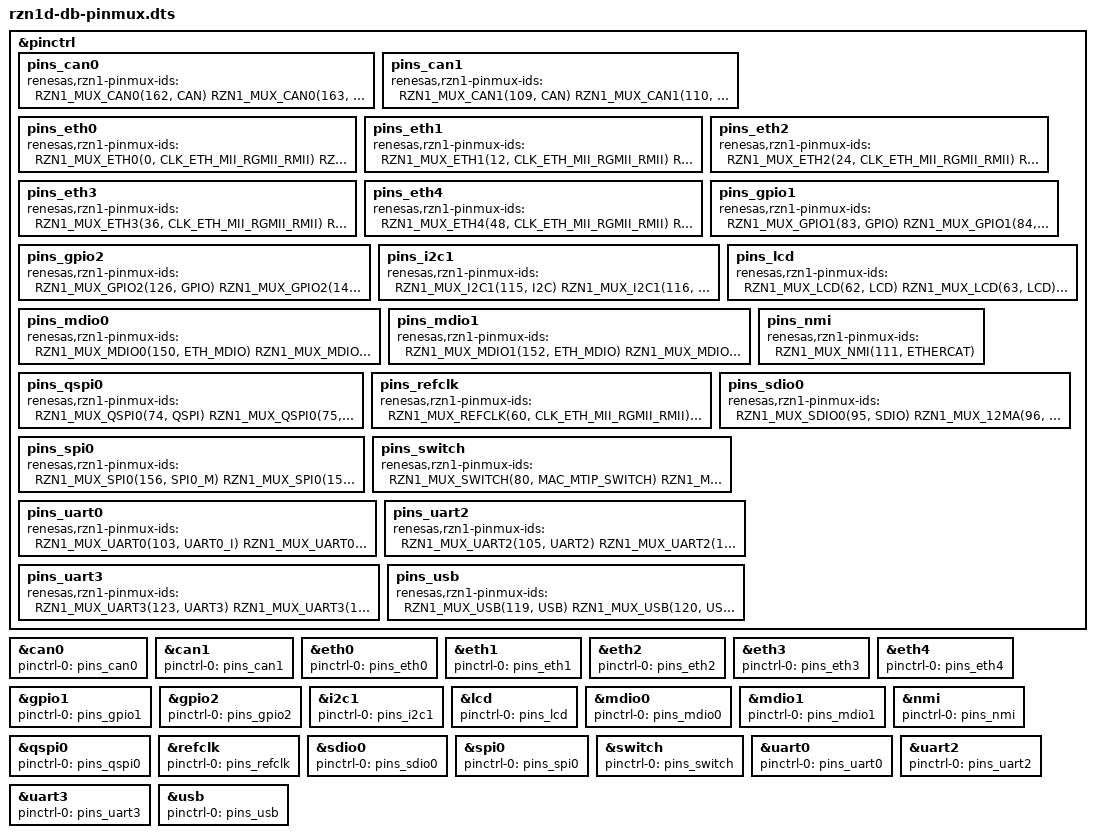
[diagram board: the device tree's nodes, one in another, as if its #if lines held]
/*
 * This file was autogenerated
 * DO NOT EDIT
 * (C) 2015-2016 Renesas Electronics Europe, LTD
 * All rights reserved.
 *
 * Redistribution and use in source and binary forms, with or without
 * modification, are permitted provided that the following conditions are met:
 *
 * 1. Redistributions of source code must retain the above copyright notice,
 * this list of conditions and the following disclaimer.
 *
 * 2. Redistributions in binary form must reproduce the above copyright notice,
 * this list of conditions and the following disclaimer in the documentation
 * and/or other materials provided with the distribution.
 *
 * THIS SOFTWARE IS PROVIDED BY THE COPYRIGHT HOLDERS AND CONTRIBUTORS "AS IS"
 * AND ANY EXPRESS OR IMPLIED WARRANTIES, INCLUDING, BUT NOT LIMITED TO, THE
 * IMPLIED WARRANTIES OF MERCHANTABILITY AND FITNESS FOR A PARTICULAR PURPOSE
 * ARE DISCLAIMED. IN NO EVENT SHALL THE COPYRIGHT HOLDER OR CONTRIBUTORS BE
 * LIABLE FOR ANY DIRECT, INDIRECT, INCIDENTAL, SPECIAL, EXEMPLARY, OR
 * CONSEQUENTIAL DAMAGES (INCLUDING, BUT NOT LIMITED TO, PROCUREMENT OF
 * SUBSTITUTE GOODS OR SERVICES; LOSS OF USE, DATA, OR PROFITS; OR BUSINESS
 * INTERRUPTION) HOWEVER CAUSED AND ON ANY THEORY OF LIABILITY, WHETHER IN
 * CONTRACT, STRICT LIABILITY, OR TORT (INCLUDING NEGLIGENCE OR OTHERWISE)
 * ARISING IN ANY WAY OUT OF THE USE OF THIS SOFTWARE, EVEN IF ADVISED OF THE
 * POSSIBILITY OF SUCH DAMAGE.
 */

#include "rzn1.dtsi"

/*
 * AUTOGENERATED DO NOT EDIT
 *
 * Renesas RZ/N1D Demo Board
 * This file only sets the pin function by default.
 *
 * You can override the default mux pullup/down and drive by
 * defining the following macros in the board file before
 * including this.
 */

#ifndef RZN1_MUX_DEFAULT
#define RZN1_MUX_DEFAULT RZN1_MUX
#endif

#ifndef RZN1_MUX_CAN0
#define RZN1_MUX_CAN0 RZN1_MUX_6MA
#endif
#ifndef RZN1_MUX_CAN1
#define RZN1_MUX_CAN1 RZN1_MUX_6MA
#endif
#ifndef RZN1_MUX_ETH0
#define RZN1_MUX_ETH0 RZN1_MUX_PNONE_6MA
#endif
#ifndef RZN1_MUX_ETH1
#define RZN1_MUX_ETH1 RZN1_MUX_PNONE_6MA
#endif
#ifndef RZN1_MUX_ETH2
#define RZN1_MUX_ETH2 RZN1_MUX_PNONE_6MA
#endif
#ifndef RZN1_MUX_ETH3
#define RZN1_MUX_ETH3 RZN1_MUX_PNONE_6MA
#endif
#ifndef RZN1_MUX_ETH4
#define RZN1_MUX_ETH4 RZN1_MUX_PNONE_6MA
#endif
#ifndef RZN1_MUX_GPIO
#define RZN1_MUX_GPIO RZN1_MUX_DEFAULT
#endif
#ifndef RZN1_MUX_GPIO1
#define RZN1_MUX_GPIO1 RZN1_MUX_GPIO
#endif
#ifndef RZN1_MUX_GPIO2
#define RZN1_MUX_GPIO2 RZN1_MUX_GPIO
#endif
#ifndef RZN1_MUX_I2C1
#define RZN1_MUX_I2C1 RZN1_MUX_12MA
#endif
#ifndef RZN1_MUX_LCD
#define RZN1_MUX_LCD RZN1_MUX_DEFAULT
#endif
#ifndef RZN1_MUX_MDIO
#define RZN1_MUX_MDIO RZN1_MUX_DEFAULT
#endif
#ifndef RZN1_MUX_MDIO0
#define RZN1_MUX_MDIO0 RZN1_MUX_MDIO
#endif
#ifndef RZN1_MUX_MDIO1
#define RZN1_MUX_MDIO1 RZN1_MUX_MDIO
#endif
#ifndef RZN1_MUX_NMI
#define RZN1_MUX_NMI RZN1_MUX_DEFAULT
#endif
#ifndef RZN1_MUX_QSPI0
#define RZN1_MUX_QSPI0 RZN1_MUX_PNONE
#endif
#ifndef RZN1_MUX_REFCLK
#define RZN1_MUX_REFCLK RZN1_MUX_PNONE
#endif
#ifndef RZN1_MUX_SDIO
#define RZN1_MUX_SDIO RZN1_MUX_DEFAULT
#endif
#ifndef RZN1_MUX_SDIO0
#define RZN1_MUX_SDIO0 RZN1_MUX_SDIO
#endif
#ifndef RZN1_MUX_SPI
#define RZN1_MUX_SPI RZN1_MUX_DEFAULT
#endif
#ifndef RZN1_MUX_SPI0
#define RZN1_MUX_SPI0 RZN1_MUX_SPI
#endif
#ifndef RZN1_MUX_SWITCH
#define RZN1_MUX_SWITCH RZN1_MUX_DEFAULT
#endif
#ifndef RZN1_MUX_UART0
#define RZN1_MUX_UART0 RZN1_MUX_PNONE
#endif
#ifndef RZN1_MUX_UART2
#define RZN1_MUX_UART2 RZN1_MUX_PNONE
#endif
#ifndef RZN1_MUX_UART
#define RZN1_MUX_UART RZN1_MUX_DEFAULT
#endif
#ifndef RZN1_MUX_UART3
#define RZN1_MUX_UART3 RZN1_MUX_UART
#endif
#ifndef RZN1_MUX_USB
#define RZN1_MUX_USB RZN1_MUX_DEFAULT
#endif

&pinctrl {
	pins_can0: pins_can0 {
		renesas,rzn1-pinmux-ids = <
			RZN1_MUX_CAN0(162, CAN)		/* CAN0_TXD */
			RZN1_MUX_CAN0(163, CAN)		/* CAN0_RXD */
		>;
	};
	pins_can1: pins_can1 {
		renesas,rzn1-pinmux-ids = <
			RZN1_MUX_CAN1(109, CAN)		/* CAN1_TXD */
			RZN1_MUX_CAN1(110, CAN)		/* CAN1_RXD */
		>;
	};
	pins_eth0: pins_eth0 {
		renesas,rzn1-pinmux-ids = <
			RZN1_MUX_ETH0(0, CLK_ETH_MII_RGMII_RMII)	/* ETH0_TXCLK */
			RZN1_MUX_ETH0(1, CLK_ETH_MII_RGMII_RMII)	/* ETH0_TXD[0] */
			RZN1_MUX_ETH0(2, CLK_ETH_MII_RGMII_RMII)	/* ETH0_TXD[1] */
			RZN1_MUX_ETH0(3, CLK_ETH_MII_RGMII_RMII)	/* ETH0_TXD[2] */
			RZN1_MUX_ETH0(4, CLK_ETH_MII_RGMII_RMII)	/* ETH0_TXD[3] */
			RZN1_MUX_ETH0(5, CLK_ETH_MII_RGMII_RMII)	/* ETH0_TXEN */
			RZN1_MUX_ETH0(6, CLK_ETH_MII_RGMII_RMII)	/* ETH0_RXCLK */
			RZN1_MUX_ETH0(7, CLK_ETH_MII_RGMII_RMII)	/* ETH0_RXD[0] */
			RZN1_MUX_ETH0(8, CLK_ETH_MII_RGMII_RMII)	/* ETH0_RXD[1] */
			RZN1_MUX_ETH0(9, CLK_ETH_MII_RGMII_RMII)	/* ETH0_RXD[2] */
			RZN1_MUX_ETH0(10, CLK_ETH_MII_RGMII_RMII)	/* ETH0_RXD[3] */
			RZN1_MUX_ETH0(11, CLK_ETH_MII_RGMII_RMII)	/* ETH0_RXDV */
		>;
	};
	pins_eth1: pins_eth1 {
		renesas,rzn1-pinmux-ids = <
			RZN1_MUX_ETH1(12, CLK_ETH_MII_RGMII_RMII)	/* ETH1_TXCLK */
			RZN1_MUX_ETH1(13, CLK_ETH_MII_RGMII_RMII)	/* ETH1_TXD[0] */
			RZN1_MUX_ETH1(14, CLK_ETH_MII_RGMII_RMII)	/* ETH1_TXD[1] */
			RZN1_MUX_ETH1(15, CLK_ETH_MII_RGMII_RMII)	/* ETH1_TXD[2] */
			RZN1_MUX_ETH1(16, CLK_ETH_MII_RGMII_RMII)	/* ETH1_TXD[3] */
			RZN1_MUX_ETH1(17, CLK_ETH_MII_RGMII_RMII)	/* ETH1_TXEN */
			RZN1_MUX_ETH1(18, CLK_ETH_MII_RGMII_RMII)	/* ETH1_RXCLK */
			RZN1_MUX_ETH1(19, CLK_ETH_MII_RGMII_RMII)	/* ETH1_RXD[0] */
			RZN1_MUX_ETH1(20, CLK_ETH_MII_RGMII_RMII)	/* ETH1_RXD[1] */
			RZN1_MUX_ETH1(21, CLK_ETH_MII_RGMII_RMII)	/* ETH1_RXD[2] */
			RZN1_MUX_ETH1(22, CLK_ETH_MII_RGMII_RMII)	/* ETH1_RXD[3] */
			RZN1_MUX_ETH1(23, CLK_ETH_MII_RGMII_RMII)	/* ETH1_RXDV */
		>;
	};
	pins_eth2: pins_eth2 {
		renesas,rzn1-pinmux-ids = <
			RZN1_MUX_ETH2(24, CLK_ETH_MII_RGMII_RMII)	/* ETH2_TXCLK */
			RZN1_MUX_ETH2(25, CLK_ETH_MII_RGMII_RMII)	/* ETH2_TXD[0] */
			RZN1_MUX_ETH2(26, CLK_ETH_MII_RGMII_RMII)	/* ETH2_TXD[1] */
			RZN1_MUX_ETH2(27, CLK_ETH_MII_RGMII_RMII)	/* ETH2_TXD[2] */
			RZN1_MUX_ETH2(28, CLK_ETH_MII_RGMII_RMII)	/* ETH2_TXD[3] */
			RZN1_MUX_ETH2(29, CLK_ETH_MII_RGMII_RMII)	/* ETH2_TXEN */
			RZN1_MUX_ETH2(30, CLK_ETH_MII_RGMII_RMII)	/* ETH2_RXCLK */
			RZN1_MUX_ETH2(31, CLK_ETH_MII_RGMII_RMII)	/* ETH2_RXD[0] */
			RZN1_MUX_ETH2(32, CLK_ETH_MII_RGMII_RMII)	/* ETH2_RXD[1] */
			RZN1_MUX_ETH2(33, CLK_ETH_MII_RGMII_RMII)	/* ETH2_RXD[2] */
			RZN1_MUX_ETH2(34, CLK_ETH_MII_RGMII_RMII)	/* ETH2_RXD[3] */
			RZN1_MUX_ETH2(35, CLK_ETH_MII_RGMII_RMII)	/* ETH2_RXDV */
		>;
	};
	pins_eth3: pins_eth3 {
		renesas,rzn1-pinmux-ids = <
			RZN1_MUX_ETH3(36, CLK_ETH_MII_RGMII_RMII)	/* ETH3_TXCLK */
			RZN1_MUX_ETH3(37, CLK_ETH_MII_RGMII_RMII)	/* ETH3_TXD[0] */
			RZN1_MUX_ETH3(38, CLK_ETH_MII_RGMII_RMII)	/* ETH3_TXD[1] */
			RZN1_MUX_ETH3(39, CLK_ETH_MII_RGMII_RMII)	/* ETH3_TXD[2] */
			RZN1_MUX_ETH3(40, CLK_ETH_MII_RGMII_RMII)	/* ETH3_TXD[3] */
			RZN1_MUX_ETH3(41, CLK_ETH_MII_RGMII_RMII)	/* ETH3_TXEN */
			RZN1_MUX_ETH3(42, CLK_ETH_MII_RGMII_RMII)	/* ETH3_RXCLK */
			RZN1_MUX_ETH3(43, CLK_ETH_MII_RGMII_RMII)	/* ETH3_RXD[0] */
			RZN1_MUX_ETH3(44, CLK_ETH_MII_RGMII_RMII)	/* ETH3_RXD[1] */
			RZN1_MUX_ETH3(45, CLK_ETH_MII_RGMII_RMII)	/* ETH3_RXD[2] */
			RZN1_MUX_ETH3(46, CLK_ETH_MII_RGMII_RMII)	/* ETH3_RXD[3] */
			RZN1_MUX_ETH3(47, CLK_ETH_MII_RGMII_RMII)	/* ETH3_RXDV */
		>;
	};
	pins_eth4: pins_eth4 {
		renesas,rzn1-pinmux-ids = <
			RZN1_MUX_ETH4(48, CLK_ETH_MII_RGMII_RMII)	/* ETH4_TXCLK */
			RZN1_MUX_ETH4(49, CLK_ETH_MII_RGMII_RMII)	/* ETH4_TXD[0] */
			RZN1_MUX_ETH4(50, CLK_ETH_MII_RGMII_RMII)	/* ETH4_TXD[1] */
			RZN1_MUX_ETH4(51, CLK_ETH_MII_RGMII_RMII)	/* ETH4_TXD[2] */
			RZN1_MUX_ETH4(52, CLK_ETH_MII_RGMII_RMII)	/* ETH4_TXD[3] */
			RZN1_MUX_ETH4(53, CLK_ETH_MII_RGMII_RMII)	/* ETH4_TXEN */
			RZN1_MUX_ETH4(54, CLK_ETH_MII_RGMII_RMII)	/* ETH4_RXCLK */
			RZN1_MUX_ETH4(55, CLK_ETH_MII_RGMII_RMII)	/* ETH4_RXD[0] */
			RZN1_MUX_ETH4(56, CLK_ETH_MII_RGMII_RMII)	/* ETH4_RXD[1] */
			RZN1_MUX_ETH4(57, CLK_ETH_MII_RGMII_RMII)	/* ETH4_RXD[2] */
			RZN1_MUX_ETH4(58, CLK_ETH_MII_RGMII_RMII)	/* ETH4_RXD[3] */
			RZN1_MUX_ETH4(59, CLK_ETH_MII_RGMII_RMII)	/* ETH4_RXDV */
		>;
	};
	pins_gpio1: pins_gpio1 {
		renesas,rzn1-pinmux-ids = <
			RZN1_MUX_GPIO1(83, GPIO)	/* GPIO1B[14] */
			RZN1_MUX_GPIO1(84, GPIO)	/* GPIO1B[15] */
			RZN1_MUX_GPIO1(85, GPIO)	/* GPIO1B[16] */
			RZN1_MUX_GPIO1(86, GPIO)	/* GPIO1B[17] */
			RZN1_MUX_GPIO1(87, GPIO)	/* GPIO1B[18] */
			RZN1_MUX_GPIO1(88, GPIO)	/* GPIO1B[19] */
			RZN1_MUX_GPIO1(89, GPIO)	/* GPIO1B[20] */
			RZN1_MUX_GPIO1(90, GPIO)	/* GPIO1B[21] */
			RZN1_MUX_GPIO1(91, GPIO)	/* GPIO1B[22] */
			RZN1_MUX_GPIO1(92, GPIO)	/* GPIO1B[23] */
			RZN1_MUX_GPIO1(93, GPIO)	/* GPIO1B[24] */
			RZN1_MUX_GPIO1(94, GPIO)	/* Eth PHY Reset (GPIO1B[25]) */
			RZN1_MUX_GPIO1(117, GPIO)	/* GPIO1A[27] */
			RZN1_MUX_GPIO1(118, GPIO)	/* Eth3 IRQ (GPIO1A[28]) */
			RZN1_MUX_GPIO1(154, GPIO)	/* MDC PHY1 GPIO (GPIO1B[30]) */
			RZN1_MUX_GPIO1(155, GPIO)	/* MDIO PHY1 GPIO (GPIO1B[31]) */
		>;
	};
	pins_gpio2: pins_gpio2 {
		renesas,rzn1-pinmux-ids = <
			RZN1_MUX_GPIO2(126, GPIO)	/* Eth2 IRQ (GPIO2A[4]) */
			RZN1_MUX_GPIO2(146, GPIO)	/* Eth1 IRQ (GPIO2A[24]) */
			RZN1_MUX_GPIO2(147, GPIO)	/* Eth4 IRQ (GPIO2A[25]) */
			RZN1_MUX_GPIO2(148, GPIO)	/* Touch IRQ (GPIO2A[26]) */
			RZN1_MUX_GPIO2(149, GPIO)	/* Eth5 IRQ (GPIO2A[27]) */
		>;
	};
	pins_i2c1: pins_i2c1 {
		renesas,rzn1-pinmux-ids = <
			RZN1_MUX_I2C1(115, I2C)		/* I2C1_SCL */
			RZN1_MUX_I2C1(116, I2C)		/* I2C1_SDA */
		>;
	};
	pins_lcd: pins_lcd {
		renesas,rzn1-pinmux-ids = <
			RZN1_MUX_LCD(62, LCD)		/* LCD_R[1] */
			RZN1_MUX_LCD(63, LCD)		/* LCD_G[1] */
			RZN1_MUX_LCD(64, LCD)		/* LCD_B[1] */
			RZN1_MUX_LCD(65, LCD)		/* LCD_R[2] */
			RZN1_MUX_LCD(66, LCD)		/* LCD_G[2] */
			RZN1_MUX_LCD(67, LCD)		/* LCD_B[2] */
			RZN1_MUX_LCD(68, LCD)		/* LCD_R[3] */
			RZN1_MUX_LCD(69, LCD)		/* LCD_G[3] */
			RZN1_MUX_LCD(70, LCD)		/* LCD_B[3] */
			RZN1_MUX_LCD(71, LCD)		/* LCD_R[4] */
			RZN1_MUX_LCD(72, LCD)		/* LCD_G[4] */
			RZN1_MUX_LCD(73, LCD)		/* LCD_B[4] */
			RZN1_MUX_LCD(127, LCD)		/* LCD_PWM[0] */
			RZN1_MUX_LCD(128, LCD)		/* LCD_PCLK */
			RZN1_MUX_LCD(129, LCD)		/* LCD_HSYNC */
			RZN1_MUX_LCD(130, LCD)		/* LCD_VSYNC */
			RZN1_MUX_LCD(131, LCD)		/* LCD_DE */
			RZN1_MUX_LCD(132, LCD)		/* LCD_PE */
			RZN1_MUX_LCD(133, LCD)		/* LCD_PWM[1] */
			RZN1_MUX_LCD(134, LCD)		/* LCD_R[5] */
			RZN1_MUX_LCD(135, LCD)		/* LCD_R[0] */
			RZN1_MUX_LCD(136, LCD)		/* LCD_G[0] */
			RZN1_MUX_LCD(137, LCD)		/* LCD_B[0] */
			RZN1_MUX_LCD(138, LCD)		/* LCD_R[6] */
			RZN1_MUX_LCD(139, LCD)		/* LCD_G[6] */
			RZN1_MUX_LCD(140, LCD)		/* LCD_B[6] */
			RZN1_MUX_LCD(141, LCD)		/* LCD_R[7] */
			RZN1_MUX_LCD(142, LCD)		/* LCD_G[7] */
			RZN1_MUX_LCD(143, LCD)		/* LCD_B[7] */
			RZN1_MUX_LCD(144, LCD)		/* LCD_G[5] */
			RZN1_MUX_LCD(145, LCD)		/* LCD_B[5] */
		>;
	};
	pins_mdio0: pins_mdio0 {
		renesas,rzn1-pinmux-ids = <
			RZN1_MUX_MDIO0(150, ETH_MDIO)	/* MDIO0_MDC */
			RZN1_MUX_MDIO0(151, ETH_MDIO)	/* MDIO0_MDIO */
			RZN1_MUX_MDIO0(170, MDIO_MUX_MAC0)	/* MDIO0_MUX_MAC0 */
		>;
	};
	pins_mdio1: pins_mdio1 {
		renesas,rzn1-pinmux-ids = <
			RZN1_MUX_MDIO1(152, ETH_MDIO)	/* MDIO1_MDC */
			RZN1_MUX_MDIO1(153, ETH_MDIO)	/* MDIO1_MDIO */
			RZN1_MUX_MDIO1(171, MDIO_MUX_SWITCH)	/* MDIO1_MUX_SWITCH */
		>;
	};
	pins_nmi: pins_nmi {
		renesas,rzn1-pinmux-ids = <
			RZN1_MUX_NMI(111, ETHERCAT)	/* NMI_CORTEXM[3] */
		>;
	};
	pins_qspi0: pins_qspi0 {
		renesas,rzn1-pinmux-ids = <
			RZN1_MUX_QSPI0(74, QSPI)	/* QSPI0_CS_N[0] */
			RZN1_MUX_QSPI0(75, QSPI)	/* QSPI0_IO[3] */
			RZN1_MUX_QSPI0(76, QSPI)	/* QSPI0_IO[2] */
			RZN1_MUX_QSPI0(77, QSPI)	/* QSPI0_IO[1] */
			RZN1_MUX_QSPI0(78, QSPI)	/* QSPI0_IO[0] */
			RZN1_MUX_QSPI0(79, QSPI)	/* QSPI0_CLK */
		>;
	};
	pins_refclk: pins_refclk {
		renesas,rzn1-pinmux-ids = <
			RZN1_MUX_REFCLK(60, CLK_ETH_MII_RGMII_RMII)	/* REFCLK_RGMII */
			RZN1_MUX_REFCLK(61, CLK_ETH_NAND)	/* REFCLK_MII[1] */
		>;
	};
	pins_sdio0: pins_sdio0 {
		renesas,rzn1-pinmux-ids = <
			RZN1_MUX_SDIO0(95, SDIO)	/* SDIO0_CMD */
			RZN1_MUX_12MA(96, SDIO)		/* SDIO0_CLK */
			RZN1_MUX_SDIO0(97, SDIO)	/* SDIO0_IO[0] */
			RZN1_MUX_SDIO0(98, SDIO)	/* SDIO0_IO[1] */
			RZN1_MUX_SDIO0(99, SDIO)	/* SDIO0_IO[2] */
			RZN1_MUX_SDIO0(100, SDIO)	/* SDIO0_IO[3] */
			RZN1_MUX_SDIO0(101, SDIO_E)	/* SDIO0_CD_N */
			RZN1_MUX_SDIO0(102, SDIO_E)	/* SDIO0_WP */
		>;
	};
	pins_spi0: pins_spi0 {
		renesas,rzn1-pinmux-ids = <
			RZN1_MUX_SPI0(156, SPI0_M)	/* SPI0_CLK */
			RZN1_MUX_SPI0(157, SPI0_M)	/* SPI0_MOSI */
			RZN1_MUX_SPI0(158, SPI0_M)	/* SPI0_MISO */
			RZN1_MUX_SPI0(159, SPI0_M)	/* SPI0_SS_N[0] */
		>;
	};
	pins_switch: pins_switch {
		renesas,rzn1-pinmux-ids = <
			RZN1_MUX_SWITCH(80, MAC_MTIP_SWITCH)	/* SWITCH_MII_LINK[5] */
			RZN1_MUX_SWITCH(81, MAC_MTIP_SWITCH)	/* SWITCH_MII_LINK[4] */
			RZN1_MUX_SWITCH(82, MAC_MTIP_SWITCH)	/* SWITCH_MII_LINK[3] */
			RZN1_MUX_SWITCH(114, MAC_MTIP_SWITCH)	/* SWITCH_MII_LINK[2] */
		>;
	};
	pins_uart0: pins_uart0 {
		renesas,rzn1-pinmux-ids = <
			RZN1_MUX_UART0(103, UART0_I)	/* UART0_TXD */
			RZN1_MUX_UART0(104, UART0_I)	/* UART0_RXD */
		>;
	};
	pins_uart2: pins_uart2 {
		renesas,rzn1-pinmux-ids = <
			RZN1_MUX_UART2(105, UART2)	/* UART2_TXD */
			RZN1_MUX_UART2(106, UART2)	/* UART2_RXD */
			RZN1_MUX_UART2(107, UART2)	/* UART2_RTS_N */
			RZN1_MUX_UART2(108, UART2)	/* UART2_CTS_N */
		>;
	};
	pins_uart3: pins_uart3 {
		renesas,rzn1-pinmux-ids = <
			RZN1_MUX_UART3(123, UART3)	/* UART3_TXD */
			RZN1_MUX_UART3(124, UART3)	/* UART3_RXD */
			RZN1_MUX_UART3(125, UART3)	/* UART3_RTS_N */
		>;
	};
	pins_usb: pins_usb {
		renesas,rzn1-pinmux-ids = <
			RZN1_MUX_USB(119, USB)		/* USB_PPON[1] */
			RZN1_MUX_USB(120, USB)		/* USB_OC[1] */
			RZN1_MUX_USB(121, USB)		/* USB_PPON[2] */
			RZN1_MUX_USB(122, USB)		/* USB_OC[2] */
		>;
	};
};

&can0 {
	pinctrl-names = "default";
	pinctrl-0 = <&pins_can0>;
};
&can1 {
	pinctrl-names = "default";
	pinctrl-0 = <&pins_can1>;
};
&eth0 {
	pinctrl-names = "default";
	pinctrl-0 = <&pins_eth0>;
};
&eth1 {
	pinctrl-names = "default";
	pinctrl-0 = <&pins_eth1>;
};
&eth2 {
	pinctrl-names = "default";
	pinctrl-0 = <&pins_eth2>;
};
&eth3 {
	pinctrl-names = "default";
	pinctrl-0 = <&pins_eth3>;
};
&eth4 {
	pinctrl-names = "default";
	pinctrl-0 = <&pins_eth4>;
};
&gpio1 {
	pinctrl-names = "default";
	pinctrl-0 = <&pins_gpio1>;
};
&gpio2 {
	pinctrl-names = "default";
	pinctrl-0 = <&pins_gpio2>;
};
&i2c1 {
	pinctrl-names = "default";
	pinctrl-0 = <&pins_i2c1>;
};
&lcd {
	pinctrl-names = "default";
	pinctrl-0 = <&pins_lcd>;
};
&mdio0 {
	pinctrl-names = "default";
	pinctrl-0 = <&pins_mdio0>;
};
&mdio1 {
	pinctrl-names = "default";
	pinctrl-0 = <&pins_mdio1>;
};
&nmi {
	pinctrl-names = "default";
	pinctrl-0 = <&pins_nmi>;
};
&qspi0 {
	pinctrl-names = "default";
	pinctrl-0 = <&pins_qspi0>;
};
&refclk {
	pinctrl-names = "default";
	pinctrl-0 = <&pins_refclk>;
};
&sdio0 {
	pinctrl-names = "default";
	pinctrl-0 = <&pins_sdio0>;
};
&spi0 {
	pinctrl-names = "default";
	pinctrl-0 = <&pins_spi0>;
};
&switch {
	pinctrl-names = "default";
	pinctrl-0 = <&pins_switch>;
};
&uart0 {
	pinctrl-names = "default";
	pinctrl-0 = <&pins_uart0>;
};
&uart2 {
	pinctrl-names = "default";
	pinctrl-0 = <&pins_uart2>;
};
&uart3 {
	pinctrl-names = "default";
	pinctrl-0 = <&pins_uart3>;
};
&usb {
	pinctrl-names = "default";
	pinctrl-0 = <&pins_usb>;
};

/*
 * This is the compressed Renesas Pinmux Web App data structure; this is
 * used to allow uploading this file back into the web app, make some
 * more changes and generate/save the DTS again. It is not used by Linux
 * in any way.
 */
#ifdef JSON_PRESET
N4IgdghgtgpiBcIBKMwwM4XQAiQLQHoA5ARgBFsyYoB7bAIRogCcATEAGhAAcIBjANYQA5nEQwALAAYpnHjGYBLbgAsFEADboEAb
RABhAIKk5RogCY5AUQAqACRLX7lrrbsBmJ3YleArHIBxAAUASQB5FxBg8M8uEPN9SIAZfTI5AFkycMcuTPDIonSQuQBFAGVQnOQr
ADF9JIBpOTKssKqKkPaAdRCbfTs5AFVDJBsq4dHYkAmbHy5BsvoQAF0uYW5FGgB9SFhteFAATktEKwAXFXdsEKQSuRJzR1OL7CC7
AE1cDBgz+/MANgQIEy+leHxI2GiYT+AHYgXkwmD3hCofd3CcQOcVOZrrd7r4MViITc7lwSL5PM8VBJcaSQOSfIgbDQAK58FS0/H+
Km+TkAXzWGxo+x0MN8EhIMP+HDFEphMJl4slAA5FXLDmqSMqpJrlSRdeZde5dRJdb5ddLZVqFVblarbRqrYcdU79U7DU7jU7TU7z
U7LUrDjbA/bA47xeYZGrI26I1IPXGvXGfXG/XGAxJI8HM1JQznw5mSC6IyRY4WE4Wk4WU4W04WM49s48848C+ZI9HHp2K+2q+2a+
26+2G+Ym+YW+Y2+5i5n3GXzOjo+4++4B+5zb5fFLxxxNzC7ebV+5/tKj/8FWfVWeNUeYTrb/rb4bb8bb6bb4eJO4pRxbwrN3q4q7
r4gEbiB5LSgB5L/uBIHAYBGq+EW5imkh8Ybsh0oSFKhwathd46vhUj6kRhpEcaRGmkR5pEVh8pSAqRGqkReHykWv4Sl+HASMcyqH
KenGfiQEgCcJF6cVe/wkEGv5SYcqq+P8o6HPqinKYaikUhSu7/FpqG6euG4GYpHAoRIIEamZvjOr+imHIedmnnZ/5FnBvhSP8uEb
h5uF0TCy7cfKq6yfJr6ecq77hYe4VYeS9ncXFsXWYx8qZhxX6PhIX7PllAWrl+765Z+X4CV+4lfleuU3ll0jpRKdU5bldWFVlxUi
XV5USJVWWsdugVShR8r/FRQ3Re5z66VIYXuZF7k0fKd79TCJESna3GrXhEo2Vl0n6mZw2GvtXFIUpkEEqWyx8kAA
#endif
